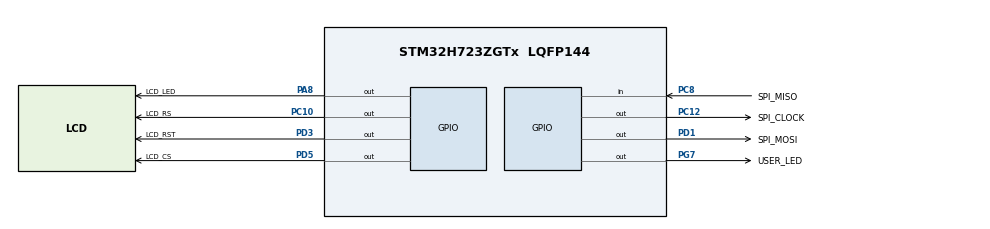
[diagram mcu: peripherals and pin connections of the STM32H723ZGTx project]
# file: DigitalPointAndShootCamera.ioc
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CORTEX_M7.default_mode_Activation=1
Mcu.Family=STM32H7
Mcu.Name=STM32H723ZGTx
Mcu.Package=LQFP144
NVIC.PriorityGroup=NVIC_PRIORITYGROUP_4
NVIC.TIM16_IRQn=true\:0\:0\:false\:false\:true\:true\:true\:true
PA8.GPIO_Label=LCD_LED
PA8.Signal=GPIO_Output
PC10.GPIO_Label=LCD_RS
PC10.Signal=GPIO_Output
PC12.GPIO_Label=SPI_CLOCK
PC12.Signal=GPIO_Output
PC8.GPIO_Label=SPI_MISO
PC8.Signal=GPIO_Input
PD1.GPIO_Label=SPI_MOSI
PD1.Signal=GPIO_Output
PD3.GPIO_Label=LCD_RST
PD3.Signal=GPIO_Output
PD5.GPIO_Label=LCD_CS
PD5.Signal=GPIO_Output
PG7.GPIO_Label=USER_LED
PG7.Signal=GPIO_Output
ProjectManager.HeapSize=0x200
ProjectManager.StackSize=0x400
ProjectManager.TargetToolchain=STM32CubeIDE
RCC.ADCFreq_Value=129000000
RCC.APB1Freq_Value=137500000
RCC.APB2Freq_Value=137500000
RCC.APB3Freq_Value=137500000
RCC.APB4Freq_Value=137500000
RCC.CortexFreq_Value=550000000
RCC.D1PPRE=RCC_APB3_DIV2
RCC.D2PPRE1=RCC_APB1_DIV2
RCC.D2PPRE2=RCC_APB2_DIV2
RCC.D3PPRE=RCC_APB4_DIV2
RCC.DIVM1=4
RCC.DIVN1=34
RCC.DIVP1=1
RCC.HCLKFreq_Value=275000000
RCC.HPRE=RCC_HCLK_DIV2
RCC.PLL2FRACN=0
RCC.PLL3FRACN=0
RCC.PLLFRACN=3072
RCC.SYSCLKFreq_VALUE=550000000
RCC.SYSCLKSource=RCC_SYSCLKSOURCE_PLLCLK
RCC.USBFreq_Value=275000000
TIM16.Period=500 - 1
TIM16.Prescaler=55 - 1
VP_MEMORYMAP_VS_MEMORYMAP.Mode=CurAppReg
VP_TIM16_VS_ClockSourceINT.Mode=Enable_Timer
board=custom

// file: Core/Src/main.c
/* USER CODE BEGIN Header */
/**
  ******************************************************************************
  * @file           : main.c
  * @brief          : Main program body
  ******************************************************************************
  * @attention
  *
  * Copyright (c) 2025 STMicroelectronics.
  * All rights reserved.
  *
  * This software is licensed under terms that can be found in the LICENSE file
  * in the root directory of this software component.
  * If no LICENSE file comes with this software, it is provided AS-IS.
  *
  ******************************************************************************
  */
/* USER CODE END Header */
#include "main.h"

TIM_HandleTypeDef htim16;

void SystemClock_Config(void);
static void MPU_Config(void);
static void MX_GPIO_Init(void);
static void MX_TIM16_Init(void);

int main(void)
{

  /* MPU Configuration--------------------------------------------------------*/
  MPU_Config();

  /* MCU Configuration--------------------------------------------------------*/

  /* Reset of all peripherals, Initializes the Flash interface and the Systick. */
  HAL_Init();

  /* Configure the system clock */
  SystemClock_Config();

  /* Initialize all configured peripherals */
  MX_GPIO_Init();
  MX_TIM16_Init();
  /* USER CODE BEGIN 2 */

  HAL_TIM_Base_Start_IT(&htim16);

  /* USER CODE END 2 */

  /* Infinite loop */
  /* USER CODE BEGIN WHILE */
  while (1)
  {

//	  HAL_GPIO_WritePin(SPI_CLOCK_GPIO_Port, SPI_CLOCK_Pin, GPIO_PIN_SET);
    /* USER CODE END WHILE */

  }
}

void SystemClock_Config(void)
{
  RCC_OscInitTypeDef RCC_OscInitStruct = {0};
  RCC_ClkInitTypeDef RCC_ClkInitStruct = {0};

  /** Supply configuration update enable
  */
  HAL_PWREx_ConfigSupply(PWR_LDO_SUPPLY);

  /** Configure the main internal regulator output voltage
  */
  __HAL_PWR_VOLTAGESCALING_CONFIG(PWR_REGULATOR_VOLTAGE_SCALE0);

  while(!__HAL_PWR_GET_FLAG(PWR_FLAG_VOSRDY)) {}

  /** Initializes the RCC Oscillators according to the specified parameters
  * in the RCC_OscInitTypeDef structure.
  */
  RCC_OscInitStruct.OscillatorType = RCC_OSCILLATORTYPE_HSI;
  RCC_OscInitStruct.HSIState = RCC_HSI_DIV1;
  RCC_OscInitStruct.HSICalibrationValue = 64;
  RCC_OscInitStruct.PLL.PLLState = RCC_PLL_ON;
  RCC_OscInitStruct.PLL.PLLSource = RCC_PLLSOURCE_HSI;
  RCC_OscInitStruct.PLL.PLLM = 4;
  RCC_OscInitStruct.PLL.PLLN = 34;
  RCC_OscInitStruct.PLL.PLLP = 1;
  RCC_OscInitStruct.PLL.PLLQ = 2;
  RCC_OscInitStruct.PLL.PLLR = 2;
  RCC_OscInitStruct.PLL.PLLRGE = RCC_PLL1VCIRANGE_3;
  RCC_OscInitStruct.PLL.PLLVCOSEL = RCC_PLL1VCOWIDE;
  RCC_OscInitStruct.PLL.PLLFRACN = 3072;
  if (HAL_RCC_OscConfig(&RCC_OscInitStruct) != HAL_OK)
  {
    Error_Handler();
  }

  /** Initializes the CPU, AHB and APB buses clocks
  */
  RCC_ClkInitStruct.ClockType = RCC_CLOCKTYPE_HCLK|RCC_CLOCKTYPE_SYSCLK
                              |RCC_CLOCKTYPE_PCLK1|RCC_CLOCKTYPE_PCLK2
                              |RCC_CLOCKTYPE_D3PCLK1|RCC_CLOCKTYPE_D1PCLK1;
  RCC_ClkInitStruct.SYSCLKSource = RCC_SYSCLKSOURCE_PLLCLK;
  RCC_ClkInitStruct.SYSCLKDivider = RCC_SYSCLK_DIV1;
  RCC_ClkInitStruct.AHBCLKDivider = RCC_HCLK_DIV2;
  RCC_ClkInitStruct.APB3CLKDivider = RCC_APB3_DIV2;
  RCC_ClkInitStruct.APB1CLKDivider = RCC_APB1_DIV2;
  RCC_ClkInitStruct.APB2CLKDivider = RCC_APB2_DIV2;
  RCC_ClkInitStruct.APB4CLKDivider = RCC_APB4_DIV2;

  if (HAL_RCC_ClockConfig(&RCC_ClkInitStruct, FLASH_LATENCY_3) != HAL_OK)
  {
    Error_Handler();
  }
}

static void MX_TIM16_Init(void)
{

  htim16.Instance = TIM16;
  htim16.Init.Prescaler = 55 - 1;
  htim16.Init.CounterMode = TIM_COUNTERMODE_UP;
  htim16.Init.Period = 5 - 1;
  htim16.Init.ClockDivision = TIM_CLOCKDIVISION_DIV1;
  htim16.Init.RepetitionCounter = 0;
  htim16.Init.AutoReloadPreload = TIM_AUTORELOAD_PRELOAD_DISABLE;
  if (HAL_TIM_Base_Init(&htim16) != HAL_OK)
  {
    Error_Handler();
  }

}

static void MX_GPIO_Init(void)
{
  GPIO_InitTypeDef GPIO_InitStruct = {0};

  /* GPIO Ports Clock Enable */
  __HAL_RCC_GPIOG_CLK_ENABLE();
  __HAL_RCC_GPIOC_CLK_ENABLE();
  __HAL_RCC_GPIOA_CLK_ENABLE();
  __HAL_RCC_GPIOD_CLK_ENABLE();

  /*Configure GPIO pin Output Level */
  HAL_GPIO_WritePin(USER_LED_GPIO_Port, USER_LED_Pin, GPIO_PIN_RESET);

  /*Configure GPIO pin Output Level */
  HAL_GPIO_WritePin(LCD_LED_GPIO_Port, LCD_LED_Pin, GPIO_PIN_RESET);

  /*Configure GPIO pin Output Level */
  HAL_GPIO_WritePin(GPIOC, LCD_RS_Pin|SPI_CLOCK_Pin, GPIO_PIN_RESET);

  /*Configure GPIO pin Output Level */
  HAL_GPIO_WritePin(GPIOD, SPI_MOSI_Pin|LCD_RST_Pin|LCD_CS_Pin, GPIO_PIN_RESET);

  /*Configure GPIO pin : USER_LED_Pin */
  GPIO_InitStruct.Pin = USER_LED_Pin;
  GPIO_InitStruct.Mode = GPIO_MODE_OUTPUT_PP;
  GPIO_InitStruct.Pull = GPIO_NOPULL;
  GPIO_InitStruct.Speed = GPIO_SPEED_FREQ_LOW;
  HAL_GPIO_Init(USER_LED_GPIO_Port, &GPIO_InitStruct);

  /*Configure GPIO pin : SPI_MISO_Pin */
  GPIO_InitStruct.Pin = SPI_MISO_Pin;
  GPIO_InitStruct.Mode = GPIO_MODE_INPUT;
  GPIO_InitStruct.Pull = GPIO_NOPULL;
  HAL_GPIO_Init(SPI_MISO_GPIO_Port, &GPIO_InitStruct);

  /*Configure GPIO pin : LCD_LED_Pin */
  GPIO_InitStruct.Pin = LCD_LED_Pin;
  GPIO_InitStruct.Mode = GPIO_MODE_OUTPUT_PP;
  GPIO_InitStruct.Pull = GPIO_NOPULL;
  GPIO_InitStruct.Speed = GPIO_SPEED_FREQ_LOW;
  HAL_GPIO_Init(LCD_LED_GPIO_Port, &GPIO_InitStruct);

  /*Configure GPIO pins : LCD_RS_Pin SPI_CLOCK_Pin */
  GPIO_InitStruct.Pin = LCD_RS_Pin|SPI_CLOCK_Pin;
  GPIO_InitStruct.Mode = GPIO_MODE_OUTPUT_PP;
  GPIO_InitStruct.Pull = GPIO_NOPULL;
  GPIO_InitStruct.Speed = GPIO_SPEED_FREQ_LOW;
  HAL_GPIO_Init(GPIOC, &GPIO_InitStruct);

  /*Configure GPIO pins : SPI_MOSI_Pin LCD_RST_Pin LCD_CS_Pin */
  GPIO_InitStruct.Pin = SPI_MOSI_Pin|LCD_RST_Pin|LCD_CS_Pin;
  GPIO_InitStruct.Mode = GPIO_MODE_OUTPUT_PP;
  GPIO_InitStruct.Pull = GPIO_NOPULL;
  GPIO_InitStruct.Speed = GPIO_SPEED_FREQ_LOW;
  HAL_GPIO_Init(GPIOD, &GPIO_InitStruct);

}

/* USER CODE BEGIN 4 */

void HAL_TIM_PeriodElapsedCallback(TIM_HandleTypeDef *htim) {

	if (htim == &htim16) {

		HAL_GPIO_TogglePin(SPI_CLOCK_GPIO_Port, SPI_CLOCK_Pin);

	}

}

/* USER CODE END 4 */

 /* MPU Configuration */

void MPU_Config(void)
{
  MPU_Region_InitTypeDef MPU_InitStruct = {0};

  /* Disables the MPU */
  HAL_MPU_Disable();

  /** Initializes and configures the Region and the memory to be protected
  */
  MPU_InitStruct.Enable = MPU_REGION_ENABLE;
  MPU_InitStruct.Number = MPU_REGION_NUMBER0;
  MPU_InitStruct.BaseAddress = 0x0;
  MPU_InitStruct.Size = MPU_REGION_SIZE_4GB;
  MPU_InitStruct.SubRegionDisable = 0x87;
  MPU_InitStruct.TypeExtField = MPU_TEX_LEVEL0;
  MPU_InitStruct.AccessPermission = MPU_REGION_NO_ACCESS;
  MPU_InitStruct.DisableExec = MPU_INSTRUCTION_ACCESS_DISABLE;
  MPU_InitStruct.IsShareable = MPU_ACCESS_SHAREABLE;
  MPU_InitStruct.IsCacheable = MPU_ACCESS_NOT_CACHEABLE;
  MPU_InitStruct.IsBufferable = MPU_ACCESS_NOT_BUFFERABLE;

  HAL_MPU_ConfigRegion(&MPU_InitStruct);
  /* Enables the MPU */
  HAL_MPU_Enable(MPU_PRIVILEGED_DEFAULT);

}

void Error_Handler(void)
{
  __disable_irq();
  while (1)
  {
  }
}
